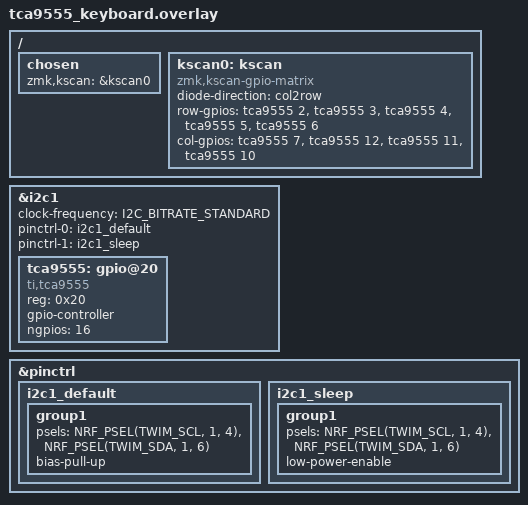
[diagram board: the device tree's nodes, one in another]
/ {
    chosen {
        zmk,kscan = &kscan0;
    };

    kscan0: kscan {
        compatible = "zmk,kscan-gpio-matrix";
        diode-direction = "col2row";

        row-gpios = <
            &tca9555 2 (GPIO_ACTIVE_HIGH)
            &tca9555 3 (GPIO_ACTIVE_HIGH)
            &tca9555 4 (GPIO_ACTIVE_HIGH)
            &tca9555 5 (GPIO_ACTIVE_HIGH)
            &tca9555 6 (GPIO_ACTIVE_HIGH)
        >;

        col-gpios = <
            &tca9555 7  (GPIO_ACTIVE_HIGH)
            &tca9555 12 (GPIO_ACTIVE_HIGH)
            &tca9555 11 (GPIO_ACTIVE_HIGH)
            &tca9555 10 (GPIO_ACTIVE_HIGH)
        >;
    };
};

&i2c1 {
    status = "okay";
    clock-frequency = <I2C_BITRATE_STANDARD>;
    pinctrl-0 = <&i2c1_default>;
    pinctrl-1 = <&i2c1_sleep>;
    pinctrl-names = "default", "sleep";

    tca9555: gpio@20 {
        compatible = "ti,tca9555";
        reg = <0x20>;
        gpio-controller;
        #gpio-cells = <2>;
        ngpios = <16>;
        status = "okay";
    };
};

&pinctrl {
    i2c1_default: i2c1_default {
        group1 {
            psels = <NRF_PSEL(TWIM_SCL, 1, 4)>,
                    <NRF_PSEL(TWIM_SDA, 1, 6)>;
            bias-pull-up;
        };
    };

    i2c1_sleep: i2c1_sleep {
        group1 {
            psels = <NRF_PSEL(TWIM_SCL, 1, 4)>,
                    <NRF_PSEL(TWIM_SDA, 1, 6)>;
            low-power-enable;
        };
    };
};
